# nrf5340_network register map
Vendor: Nordic Semiconductor; Series: nrf53; File version: 1
CPU: CM33 r0p4, little endian, MPU, no FPU, 3 interrupt priority bits, 30 interrupts
Registers are 32-bit, read-write, reset 0x0 unless marked. A register's access mark holds for its fields unless they carry their own. Offsets are from the block's base; [hi:lo] are bit positions; lines under a group give offsets from that group; {n}, {i} and the like mark numbered series.

## SWI0_NS — Software interrupt 0
Base 0x4101A000
Same registers: SWI1_NS 0x4101B000, SWI2_NS 0x4101C000, SWI3_NS 0x4101D000

## APPMUTEX_NS — MUTEX 0
Base 0x40030000
Same registers: APPMUTEX_S 0x50030000
{0x400+4i} MUTEX[{i}] (i=0..15) — Description collection: Mutex register
  [0] MUTEX — Mutex register n
    0=Unlocked (Mutex n is in unlocked state); 1=Locked (Mutex n is in locked state)

## ACL_NS — Access control lists
Base 0x41080000
{0x800+0x10*i} ACL[{i}] (i=0..7) group — Unspecified
  0x00 ADDR rw-once — Description cluster: Configure the word-aligned start address of region n to protect
    [31:0] ADDR — Valid word-aligned start address of region n to protect. Address must point to a flash page boundary.
  0x04 SIZE rw-once — Description cluster: Size of region to protect counting from address ACL[n].ADDR. Write '0' as no effect.
    [31:0] SIZE — Size of flash region n in bytes. Must be a multiple of the flash page size.
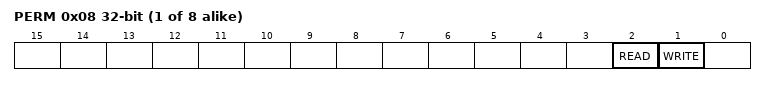
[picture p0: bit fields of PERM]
  0x08 PERM rw-once — Description cluster: Access permissions for region n as defined by start address ACL[n].ADDR and size ACL[n].SIZE
    [2] READ — Configure read permissions for region n. Write '0' has no effect.
      0=Enable (Allow read instructions to region n); 1=Disable (Block read instructions to region n)
    [1] WRITE — Configure write and erase permissions for region n. Write '0' has no effect.
      0=Enable (Allow write and erase instructions to region n); 1=Disable (Block write and erase instructions to region n)

## NVMC_NS — Non-volatile memory controller
Base 0x41080000; alternate view of ACL_NS
0x400 READY ro reset 0x1 — Ready flag
  [0] READY — NVMC is ready or busy
    0=Busy (NVMC is busy (on-going write or erase operation)); 1=Ready (NVMC is ready)
0x408 READYNEXT ro reset 0x1 — Ready flag
  [0] READYNEXT — NVMC can accept a new write operation
    0=Busy (NVMC cannot accept any write operation); 1=Ready (NVMC is ready)
0x504 CONFIG — Configuration register
  [2:0] WEN — Program memory access mode. It is strongly recommended to only activate erase and write modes when they are actively used. Enabling write or erase will invalidate the cache and keep it invalidated.
    0=Ren (Read only access); 1=Wen (Write enabled); 2=Een (Erase enabled); 4=PEen (Partial erase enabled)
0x50C ERASEALL wo — Register for erasing all non-volatile user memory
  [0] ERASEALL — Erase all non-volatile memory including UICR registers. Note that erasing must be enabled by setting CONFIG.WEN = Een before the non-volatile memory can be erased.
    0=NoOperation; 1=Erase (Start chip erase)
0x51C ERASEPAGEPARTIALCFG reset 0xA — Register for partial erase configuration
  [6:0] DURATION — Duration of the partial erase in milliseconds
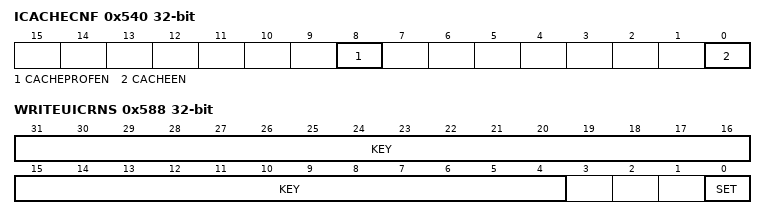
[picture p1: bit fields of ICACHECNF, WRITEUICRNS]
0x540 ICACHECNF — I-code cache configuration register
  [8] CACHEPROFEN — Cache profiling enable
    0=Disabled (Disable cache profiling); 1=Enabled (Enable cache profiling)
  [0] CACHEEN — Cache enable
    0=Disabled (Disable cache. Invalidates all cache entries.); 1=Enabled (Enable cache)
0x548 IHIT — I-code cache hit counter
  [31:0] HITS — Number of cache hits Write zero to clear
0x54C IMISS — I-code cache miss counter
  [31:0] MISSES — Number of cache misses Write zero to clear
0x584 CONFIGNS — Unspecified
  [1:0] WEN — Program memory access mode. It is strongly recommended to only activate erase and write modes when they are actively used. Enabling write or erase will invalidate the cache and keep it invalidated.
    0=Ren (Read only access); 1=Wen (Write enabled); 2=Een (Erase enabled)
0x588 WRITEUICRNS wo — Non-secure APPROTECT enable register
  [31:4] KEY — Key to write in order to validate the write operation
    0xAFBE5A7=Keyvalid (Key value)
  [0] SET — Allow non-secure code to set APPROTECT
    1=Set (Set value)

## VMC_NS — Volatile Memory controller
Base 0x41081000
{0x600+0x10*i} RAM[{i}] (i=0..3) group — Unspecified
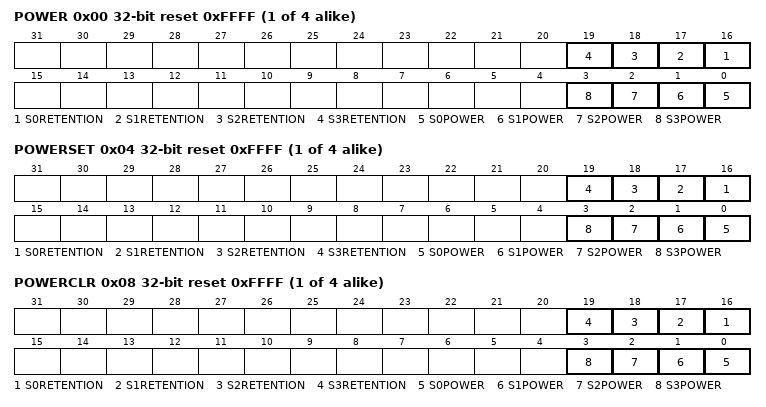
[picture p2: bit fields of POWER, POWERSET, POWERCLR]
  0x00 POWER reset 0xFFFF — Description cluster: RAM[n] power control register
    [all] fields
      0=Off; 1=On
    [n+16] S{n}RETENTION (n=0..3) — Keep retention on RAM section S{n} of RAM[n] when RAM section is switched off
    [n] S{n}POWER (n=0..3) — Keep RAM section S{n} of RAM[n] on or off in System ON mode
  0x04 POWERSET reset 0xFFFF — Description cluster: RAM[n] power control set register
    [all] fields
      1=On
    [n+16] S{n}RETENTION (n=0..3) — Keep retention on RAM section S{n} of RAM[n] when RAM section is switched off
    [n] S{n}POWER (n=0..3) — Keep RAM section S{n} of RAM[n] on or off in System ON mode
  0x08 POWERCLR reset 0xFFFF — Description cluster: RAM[n] power control clear register
    [all] fields
      1=Off
    [n+16] S{n}RETENTION (n=0..3) — Keep retention on RAM section S{n} of RAM[n] when RAM section is switched off
    [n] S{n}POWER (n=0..3) — Keep RAM section S{n} of RAM[n] on or off in System ON mode
